AUTOSAR XML (schema 4-3-0)
package /Sensors_Comp
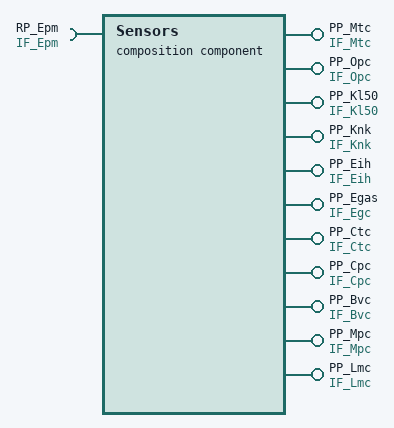
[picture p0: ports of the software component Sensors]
  composition sw component type Sensors
    9 x provide port:
      PP_Mtc: provided-interface=IF_Mtc
      PP_Opc: provided-interface=IF_Opc
      PP_Kl50: provided-interface=IF_Kl50
      PP_Knk: provided-interface=IF_Knk
      PP_Eih: provided-interface=IF_Eih
      PP_Egas: provided-interface=IF_Egc
      PP_Ctc: provided-interface=IF_Ctc
      PP_Cpc: provided-interface=IF_Cpc
      PP_Bvc: provided-interface=IF_Bvc
    require port RP_Epm: required-interface=IF_Epm
    provide port PP_Mpc: provided-interface=IF_Mpc
    provide port PP_Lmc: provided-interface=IF_Lmc
    13 x component:
      CPT_Egas: type=Egas
      CPT_Ctc: type=Ctc
      CPT_Mtc: type=Mtc
      CPT_Mpc: type=Mpc
      CPT_Cpc: type=Cpc
      CPT_Bvc: type=Bvc
      CPT_Opc: type=Opc
      CPT_Amc: type=Amc
      CPT_Kl50: type=Kl50
      CPT_Knk: type=Knk
      CPT_Lmc: type=Lmc
      CPT_Eih: type=Eih
      CPT_Egas_SensorDriver: type=EgasSensor
    connect CPT_Kl50.PP_Kl50 -> CPT_Eih.RP_Kl50
    connect CPT_Lmc.PP_Lmc -> CPT_Eih.RP_Lmc
    connect CPT_Knk.PP_Knk -> CPT_Eih.RP_Knk
    connect CPT_Egas.PP_Egc -> CPT_Eih.RP_Egas
    connect CPT_Cpc.PP_Cpc -> CPT_Eih.RP_Cpc
    connect CPT_Mpc.PP_Mpc -> CPT_Eih.RP_Mpc
    connect CPT_Ctc.PP_Ctc -> CPT_Eih.RP_Ctc
    connect CPT_Bvc.PP_Bvc -> CPT_Eih.RP_Bvc
    connect CPT_Mtc.PP_Mtc -> CPT_Eih.RP_Mtc
    connect CPT_Opc.PP_Opc -> CPT_Eih.RP_Opc
    delegate CPT_Cpc.PP_Cpc <-> outer port Sensors/PP_Cpc
    delegate CPT_Egas.PP_Egc <-> outer port PP_Egas
    delegate CPT_Cpc.RP_Epm <-> outer port Sensors/RP_Epm
    delegate CPT_Opc.PP_Opc <-> outer port Sensors/PP_Opc
    delegate CPT_Bvc.PP_Bvc <-> outer port Sensors/PP_Bvc
    delegate CPT_Mtc.PP_Mtc <-> outer port Sensors/PP_Mtc
    delegate CPT_Knk.PP_Knk <-> outer port Sensors/PP_Knk
    delegate CPT_Ctc.PP_Ctc <-> outer port Sensors/PP_Ctc
    delegate CPT_Eih.PP_Eih <-> outer port Sensors/PP_Eih
    delegate CPT_Kl50.PP_Kl50 <-> outer port Sensors/PP_Kl50
    delegate CPT_Opc.RP_Epm <-> outer port Sensors/RP_Epm
    delegate CPT_Mpc.PP_Mpc <-> outer port Sensors/PP_Mpc
    delegate CPT_Lmc.PP_Lmc <-> outer port Sensors/PP_Lmc
    connect CPT_Amc.PP_Amc -> CPT_Eih.RP_Amc
    connect CPT_Egas_SensorDriver.SP_Egas -> CPT_Egas.CP_Egc
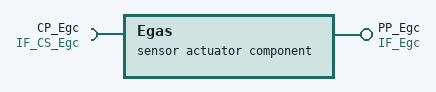
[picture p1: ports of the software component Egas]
  sensor actuator sw component type Egas
    provide port PP_Egc: provided-interface=IF_Egc
    require port CP_Egc: required-interface=IF_CS_Egc
  sensor actuator sw component type Ctc
    provide port PP_Ctc: provided-interface=IF_Ctc
  sensor actuator sw component type Mtc
    provide port PP_Mtc: provided-interface=IF_Mtc
  sensor actuator sw component type Mpc
    provide port PP_Mpc: provided-interface=IF_Mpc
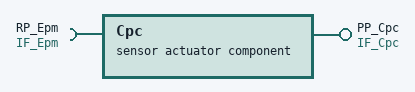
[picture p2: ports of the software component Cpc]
  sensor actuator sw component type Cpc
    provide port PP_Cpc: provided-interface=IF_Cpc
    require port RP_Epm: required-interface=IF_Epm
  sensor actuator sw component type Bvc
    provide port PP_Bvc: provided-interface=IF_Bvc
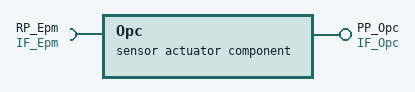
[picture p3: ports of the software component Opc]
  sensor actuator sw component type Opc
    provide port PP_Opc: provided-interface=IF_Opc
    require port RP_Epm: required-interface=IF_Epm
  sensor actuator sw component type Amc
    provide port PP_Amc: provided-interface=IF_Amc
  sensor actuator sw component type Kl50
    provide port PP_Kl50: provided-interface=IF_Kl50
  sensor actuator sw component type Knk
    provide port PP_Knk: provided-interface=IF_Knk
  sensor actuator sw component type Lmc
    provide port PP_Lmc: provided-interface=IF_Lmc
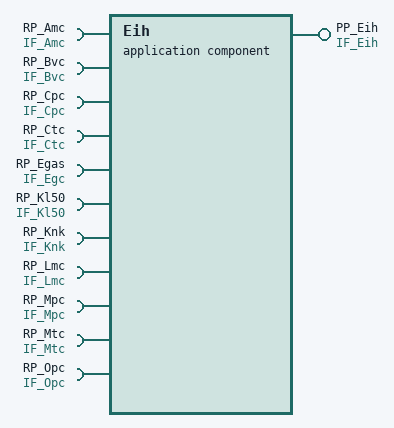
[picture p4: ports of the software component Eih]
  application sw component type Eih
    provide port PP_Eih: provided-interface=IF_Eih
    11 x require port:
      RP_Amc: required-interface=IF_Amc
      RP_Bvc: required-interface=IF_Bvc
      RP_Cpc: required-interface=IF_Cpc
      RP_Ctc: required-interface=IF_Ctc
      RP_Egas: required-interface=IF_Egc
      RP_Kl50: required-interface=IF_Kl50
      RP_Knk: required-interface=IF_Knk
      RP_Lmc: required-interface=IF_Lmc
      RP_Mpc: required-interface=IF_Mpc
      RP_Mtc: required-interface=IF_Mtc
      RP_Opc: required-interface=IF_Opc
package /Sensors_Comp/PortInterfaceMappingSets
  port interface mapping set PIMSet_Sensors
